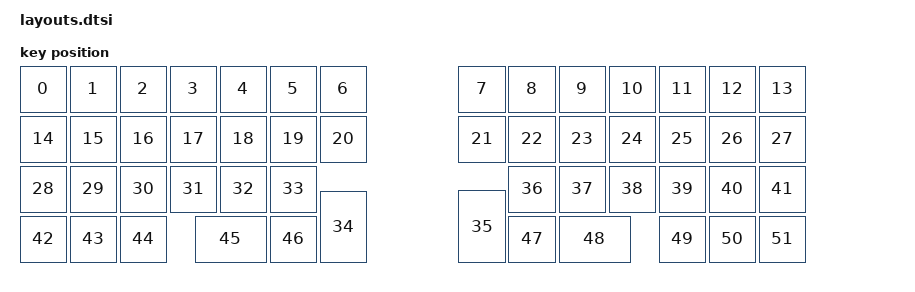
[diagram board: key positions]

#include <physical_layouts.dtsi>
/ {
    physical_layout0: physical_layout0 {
        compatible = "zmk,physical-layout";
        display-name = "Layout";
        keys
            = <&key_physical_attrs 100 100 (-12) 50 0 0 0>
			,<&key_physical_attrs 100 100 88 50 0 0 0>
			,<&key_physical_attrs 100 100 188 50 0 0 0>
			,<&key_physical_attrs 100 100 288 50 0 0 0>
			,<&key_physical_attrs 100 100 388 50 0 0 0>
			,<&key_physical_attrs 100 100 488 50 0 0 0>
			,<&key_physical_attrs 100 100 588 50 0 0 0>
			,<&key_physical_attrs 100 100 866 50 0 0 0>
			,<&key_physical_attrs 100 100 966 50 0 0 0>
			,<&key_physical_attrs 100 100 1066 50 0 0 0>
			,<&key_physical_attrs 100 100 1166 50 0 0 0>
			,<&key_physical_attrs 100 100 1266 50 0 0 0>
			,<&key_physical_attrs 100 100 1366 50 0 0 0>
			,<&key_physical_attrs 100 100 1466 50 0 0 0>
			,<&key_physical_attrs 100 100 (-12) 150 0 0 0>
			,<&key_physical_attrs 100 100 88 150 0 0 0>
			,<&key_physical_attrs 100 100 188 150 0 0 0>
			,<&key_physical_attrs 100 100 288 150 0 0 0>
			,<&key_physical_attrs 100 100 388 150 0 0 0>
			,<&key_physical_attrs 100 100 488 150 0 0 0>
			,<&key_physical_attrs 100 100 588 150 0 0 0>
			,<&key_physical_attrs 100 100 866 150 0 0 0>
			,<&key_physical_attrs 100 100 966 150 0 0 0>
			,<&key_physical_attrs 100 100 1066 150 0 0 0>
			,<&key_physical_attrs 100 100 1166 150 0 0 0>
			,<&key_physical_attrs 100 100 1266 150 0 0 0>
			,<&key_physical_attrs 100 100 1366 150 0 0 0>
			,<&key_physical_attrs 100 100 1466 150 0 0 0>
			,<&key_physical_attrs 100 100 (-12) 250 0 0 0>
			,<&key_physical_attrs 100 100 88 250 0 0 0>
			,<&key_physical_attrs 100 100 188 250 0 0 0>
			,<&key_physical_attrs 100 100 288 250 0 0 0>
			,<&key_physical_attrs 100 100 388 250 0 0 0>
			,<&key_physical_attrs 100 100 488 250 0 0 0>
			,<&key_physical_attrs 150 100 588 450 (-9000) 588 450>
			,<&key_physical_attrs 150 100 966 300 9000 966 300>
			,<&key_physical_attrs 100 100 966 250 0 0 0>
			,<&key_physical_attrs 100 100 1066 250 0 0 0>
			,<&key_physical_attrs 100 100 1166 250 0 0 0>
			,<&key_physical_attrs 100 100 1266 250 0 0 0>
			,<&key_physical_attrs 100 100 1366 250 0 0 0>
			,<&key_physical_attrs 100 100 1466 250 0 0 0>
			,<&key_physical_attrs 100 100 (-12) 350 0 0 0>
			,<&key_physical_attrs 100 100 88 350 0 0 0>
			,<&key_physical_attrs 100 100 188 350 0 0 0>
			,<&key_physical_attrs 150 100 338 350 0 0 0>
			,<&key_physical_attrs 100 100 488 350 0 0 0>
			,<&key_physical_attrs 100 100 966 350 0 0 0>
			,<&key_physical_attrs 150 100 1066 350 0 0 0>
			,<&key_physical_attrs 100 100 1266 350 0 0 0>
			,<&key_physical_attrs 100 100 1366 350 0 0 0>
			,<&key_physical_attrs 100 100 1466 350 0 0 0>
            ;
    };
};
    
